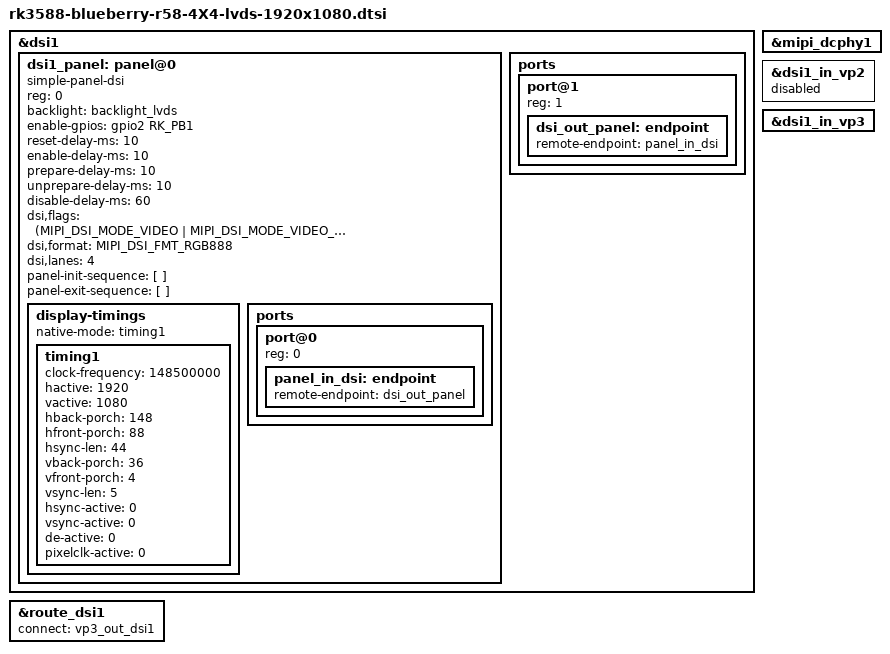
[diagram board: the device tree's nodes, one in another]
// SPDX-License-Identifier: (GPL-2.0+ OR MIT)
/*
 * Copyright (c) 2021 Rockchip Electronics Co., Ltd.
 *
 */

#include "dt-bindings/usb/pd.h"

&dsi1 {
	status = "okay";
	//rockchip,lane-rate = <1000>;
	dsi1_panel: panel@0 {
		status = "okay";
		compatible = "simple-panel-dsi";
		reg = <0>;
		backlight = <&backlight_lvds>;
		enable-gpios = <&gpio2 RK_PB1 GPIO_ACTIVE_HIGH>;
		reset-delay-ms = <10>;
		enable-delay-ms = <10>;
		prepare-delay-ms = <10>;
		unprepare-delay-ms = <10>;
		disable-delay-ms = <60>;
		dsi,flags = <(MIPI_DSI_MODE_VIDEO | MIPI_DSI_MODE_VIDEO_BURST |
			MIPI_DSI_MODE_LPM | MIPI_DSI_MODE_EOT_PACKET)>;
		dsi,format = <MIPI_DSI_FMT_RGB888>;
		dsi,lanes  = <4>;

		panel-init-sequence = [
		];

		panel-exit-sequence = [
		];

		display-timings {
			native-mode = <&timing1>;
			//					     //hfp, hs, hbp,hact,htotal,vfp, vs, vbp, vact,vtotal,pixclk_khz
			//struct video_timing video_1920x1080_60Hz   ={88, 44, 148,1920,  2200,  4,  5,  36, 1080, 1125, 148500};
			timing1: timing1 {
				clock-frequency = <148500000>;
				hactive = <1920>;
				vactive = <1080>; //<2160>;
				hback-porch = <148>;
				hfront-porch = <88>;
				hsync-len = <44>;
				vback-porch = <36>;
				vfront-porch = <4>;
				vsync-len = <5>;
				hsync-active = <0>;
				vsync-active = <0>;
				de-active = <0>;
				pixelclk-active = <0>;
				};
		};


		ports {
			#address-cells = <1>;
			#size-cells = <0>;

			port@0 {
				reg = <0>;
				panel_in_dsi: endpoint {
					remote-endpoint = <&dsi_out_panel>;
				};
			};
		};
	};

	ports {
		#address-cells = <1>;
		#size-cells = <0>;

		port@1 {
			reg = <1>;
			dsi_out_panel: endpoint {
				remote-endpoint = <&panel_in_dsi>;
			};
		};
	};

};

&dsi1 {
	status = "okay";
};

&mipi_dcphy1 {
	status = "okay";
};

&dsi1_in_vp2 {
	status = "disabled";
};

&dsi1_in_vp3 {
	status = "okay";
};

&route_dsi1 {
	status = "okay";
	connect = <&vp3_out_dsi1>;
};

